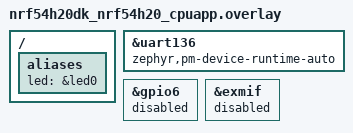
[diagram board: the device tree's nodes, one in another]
/ {
	aliases {
		led = &led0;
		/delete-property/ led1;
	};
};

/delete-node/ &led1;

&uart136 {
	zephyr,pm-device-runtime-auto;
};

&gpio6 {
	status = "disabled";
};

&exmif {
	status = "disabled";
};
